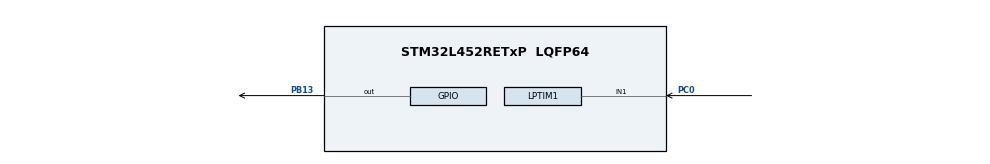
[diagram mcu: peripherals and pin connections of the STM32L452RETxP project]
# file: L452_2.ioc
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Mcu.Family=STM32L4
Mcu.Name=STM32L452RETxP
Mcu.Package=LQFP64
NVIC.LPTIM1_IRQn=true\:0\:0\:false\:false\:true\:true
NVIC.PriorityGroup=NVIC_PRIORITYGROUP_4
PA13\ (JTMS/SWDIO).Mode=Serial_Wire
PA13\ (JTMS/SWDIO).Signal=SYS_JTMS-SWDIO
PA14\ (JTCK/SWCLK).Mode=Serial_Wire
PA14\ (JTCK/SWCLK).Signal=SYS_JTCK-SWCLK
PB13.Signal=GPIO_Output
PC0.Mode=Counts_external_clock_standalone_1X_occur1
PC0.Signal=LPTIM1_IN1
ProjectManager.HeapSize=0x200
ProjectManager.StackSize=0x400
ProjectManager.TargetToolchain=MDK-ARM V5
RCC.HSE_VALUE=8000000
RCC.HSI48_VALUE=48000000
RCC.HSI_VALUE=16000000
RCC.LPTIM1CLockSelection=RCC_LPTIM1CLKSOURCE_LSI
RCC.LSE_VALUE=32768
RCC.MSI_VALUE=4000000
RCC.PWR_Regulator_Voltage_Scale=PWR_REGULATOR_VOLTAGE_SCALE2
RCC.VCOOutputFreq_Value=32000000
board=L452_2

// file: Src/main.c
/**
  ******************************************************************************
  * File Name          : main.c
  * Description        : Main program body
  ******************************************************************************
  ** This notice applies to any and all portions of this file
  * that are not between comment pairs USER CODE BEGIN and
  * USER CODE END. Other portions of this file, whether
  * inserted by the user or by software development tools
  * are owned by their respective copyright owners.
  *
  * COPYRIGHT(c) 2017 STMicroelectronics
  *
  * Redistribution and use in source and binary forms, with or without modification,
  * are permitted provided that the following conditions are met:
  *   1. Redistributions of source code must retain the above copyright notice,
  *      this list of conditions and the following disclaimer.
  *   2. Redistributions in binary form must reproduce the above copyright notice,
  *      this list of conditions and the following disclaimer in the documentation
  *      and/or other materials provided with the distribution.
  *   3. Neither the name of STMicroelectronics nor the names of its contributors
  *      may be used to endorse or promote products derived from this software
  *      without specific prior written permission.
  *
  * THIS SOFTWARE IS PROVIDED BY THE COPYRIGHT HOLDERS AND CONTRIBUTORS "AS IS"
  * AND ANY EXPRESS OR IMPLIED WARRANTIES, INCLUDING, BUT NOT LIMITED TO, THE
  * IMPLIED WARRANTIES OF MERCHANTABILITY AND FITNESS FOR A PARTICULAR PURPOSE ARE
  * DISCLAIMED. IN NO EVENT SHALL THE COPYRIGHT HOLDER OR CONTRIBUTORS BE LIABLE
  * FOR ANY DIRECT, INDIRECT, INCIDENTAL, SPECIAL, EXEMPLARY, OR CONSEQUENTIAL
  * DAMAGES (INCLUDING, BUT NOT LIMITED TO, PROCUREMENT OF SUBSTITUTE GOODS OR
  * SERVICES; LOSS OF USE, DATA, OR PROFITS; OR BUSINESS INTERRUPTION) HOWEVER
  * CAUSED AND ON ANY THEORY OF LIABILITY, WHETHER IN CONTRACT, STRICT LIABILITY,
  * OR TORT (INCLUDING NEGLIGENCE OR OTHERWISE) ARISING IN ANY WAY OUT OF THE USE
  * OF THIS SOFTWARE, EVEN IF ADVISED OF THE POSSIBILITY OF SUCH DAMAGE.
  *
  ******************************************************************************
  */

#include "main.h"
#include "stm32l4xx_hal.h"

LPTIM_HandleTypeDef hlptim1;

/* USER CODE BEGIN PV */
/* Private variables ---------------------------------------------------------*/

/* USER CODE END PV */

void SystemClock_Config(void);
static void MX_GPIO_Init(void);
static void MX_LPTIM1_Init(void);

/* USER CODE BEGIN PFP */
/* Private function prototypes -----------------------------------------------*/

/* USER CODE END PFP */

int main(void)
{

  /* MCU Configuration----------------------------------------------------------*/

  /* Reset of all peripherals, Initializes the Flash interface and the Systick. */
  HAL_Init();

  /* Configure the system clock */
  SystemClock_Config();

  /* Initialize all configured peripherals */
  MX_GPIO_Init();
  MX_LPTIM1_Init();

  /* USER CODE BEGIN 2 */
	HAL_PWREx_EnableGPIOPullUp(PWR_GPIO_A, GPIO_PIN_2);
    HAL_PWREx_EnableGPIOPullUp(PWR_GPIO_B, GPIO_PIN_3);
	HAL_PWREx_EnablePullUpPullDownConfig();

    __HAL_RCC_GPIOC_CLK_DISABLE();
    __HAL_RCC_GPIOH_CLK_DISABLE();
    __HAL_RCC_GPIOA_CLK_DISABLE();
    __HAL_RCC_GPIOE_CLK_DISABLE();
    __HAL_RCC_GPIOD_CLK_DISABLE();

	__HAL_FLASH_POWER_DOWN_ENABLE();
	HAL_LPTIM_Counter_Start_IT(&hlptim1, 4);

  /* USER CODE END 2 */

  /* Infinite loop */
  while (1)
  {

  /* USER CODE BEGIN 3 */
	HAL_PWREx_EnterSTOP2Mode(PWR_STOPENTRY_WFI);
	HAL_GPIO_TogglePin(GPIOB, GPIO_PIN_13);

  }
  /* USER CODE END 3 */

}

/** System Clock Configuration
*/
void SystemClock_Config(void)
{

  RCC_OscInitTypeDef RCC_OscInitStruct;
  RCC_ClkInitTypeDef RCC_ClkInitStruct;
  RCC_PeriphCLKInitTypeDef PeriphClkInit;

    /**Initializes the CPU, AHB and APB busses clocks
    */
  RCC_OscInitStruct.OscillatorType = RCC_OSCILLATORTYPE_LSI|RCC_OSCILLATORTYPE_MSI;
  RCC_OscInitStruct.LSIState = RCC_LSI_ON;
  RCC_OscInitStruct.MSIState = RCC_MSI_ON;
  RCC_OscInitStruct.MSICalibrationValue = 0;
  RCC_OscInitStruct.MSIClockRange = RCC_MSIRANGE_6;
  RCC_OscInitStruct.PLL.PLLState = RCC_PLL_NONE;
  if (HAL_RCC_OscConfig(&RCC_OscInitStruct) != HAL_OK)
  {
    _Error_Handler(__FILE__, __LINE__);
  }

    /**Initializes the CPU, AHB and APB busses clocks
    */
  RCC_ClkInitStruct.ClockType = RCC_CLOCKTYPE_HCLK|RCC_CLOCKTYPE_SYSCLK
                              |RCC_CLOCKTYPE_PCLK1|RCC_CLOCKTYPE_PCLK2;
  RCC_ClkInitStruct.SYSCLKSource = RCC_SYSCLKSOURCE_MSI;
  RCC_ClkInitStruct.AHBCLKDivider = RCC_SYSCLK_DIV1;
  RCC_ClkInitStruct.APB1CLKDivider = RCC_HCLK_DIV1;
  RCC_ClkInitStruct.APB2CLKDivider = RCC_HCLK_DIV1;

  if (HAL_RCC_ClockConfig(&RCC_ClkInitStruct, FLASH_LATENCY_0) != HAL_OK)
  {
    _Error_Handler(__FILE__, __LINE__);
  }

  PeriphClkInit.PeriphClockSelection = RCC_PERIPHCLK_LPTIM1;
  PeriphClkInit.Lptim1ClockSelection = RCC_LPTIM1CLKSOURCE_LSI;
  if (HAL_RCCEx_PeriphCLKConfig(&PeriphClkInit) != HAL_OK)
  {
    _Error_Handler(__FILE__, __LINE__);
  }

    /**Configure the main internal regulator output voltage
    */
  if (HAL_PWREx_ControlVoltageScaling(PWR_REGULATOR_VOLTAGE_SCALE2) != HAL_OK)
  {
    _Error_Handler(__FILE__, __LINE__);
  }

    /**Configure the Systick interrupt time
    */
  HAL_SYSTICK_Config(HAL_RCC_GetHCLKFreq()/1000);

    /**Configure the Systick
    */
  HAL_SYSTICK_CLKSourceConfig(SYSTICK_CLKSOURCE_HCLK);

  /* SysTick_IRQn interrupt configuration */
  HAL_NVIC_SetPriority(SysTick_IRQn, 0, 0);
}

/* LPTIM1 init function */
static void MX_LPTIM1_Init(void)
{

  hlptim1.Instance = LPTIM1;
  hlptim1.Init.Clock.Source = LPTIM_CLOCKSOURCE_ULPTIM;
  hlptim1.Init.Clock.Prescaler = LPTIM_PRESCALER_DIV1;
  hlptim1.Init.UltraLowPowerClock.Polarity = LPTIM_CLOCKPOLARITY_RISING;
  hlptim1.Init.UltraLowPowerClock.SampleTime = LPTIM_CLOCKSAMPLETIME_DIRECTTRANSITION;
  hlptim1.Init.Trigger.Source = LPTIM_TRIGSOURCE_SOFTWARE;
  hlptim1.Init.OutputPolarity = LPTIM_OUTPUTPOLARITY_HIGH;
  hlptim1.Init.UpdateMode = LPTIM_UPDATE_IMMEDIATE;
  hlptim1.Init.CounterSource = LPTIM_COUNTERSOURCE_EXTERNAL;
  hlptim1.Init.Input1Source = LPTIM_INPUT1SOURCE_GPIO;
  hlptim1.Init.Input2Source = LPTIM_INPUT2SOURCE_GPIO;
  if (HAL_LPTIM_Init(&hlptim1) != HAL_OK)
  {
    _Error_Handler(__FILE__, __LINE__);
  }

}

/** Configure pins as
        * Analog
        * Input
        * Output
        * EVENT_OUT
        * EXTI
        * Free pins are configured automatically as Analog (this feature is enabled through
        * the Code Generation settings)
*/
static void MX_GPIO_Init(void)
{

  GPIO_InitTypeDef GPIO_InitStruct;

  /* GPIO Ports Clock Enable */
  __HAL_RCC_GPIOC_CLK_ENABLE();
  __HAL_RCC_GPIOH_CLK_ENABLE();
  __HAL_RCC_GPIOA_CLK_ENABLE();
  __HAL_RCC_GPIOB_CLK_ENABLE();

  /*Configure GPIO pin Output Level */
  HAL_GPIO_WritePin(GPIOB, GPIO_PIN_13, GPIO_PIN_RESET);

  /*Configure GPIO pins : PC13 PC14 PC15 PC1
                           PC2 PC3 PC4 PC6
                           PC7 PC8 PC9 PC10
                           PC11 PC12 */
  GPIO_InitStruct.Pin = GPIO_PIN_13|GPIO_PIN_14|GPIO_PIN_15|GPIO_PIN_1
                          |GPIO_PIN_2|GPIO_PIN_3|GPIO_PIN_4|GPIO_PIN_6
                          |GPIO_PIN_7|GPIO_PIN_8|GPIO_PIN_9|GPIO_PIN_10
                          |GPIO_PIN_11|GPIO_PIN_12;
  GPIO_InitStruct.Mode = GPIO_MODE_ANALOG;
  GPIO_InitStruct.Pull = GPIO_NOPULL;
  HAL_GPIO_Init(GPIOC, &GPIO_InitStruct);

  /*Configure GPIO pins : PH0 PH1 PH3 */
  GPIO_InitStruct.Pin = GPIO_PIN_0|GPIO_PIN_1|GPIO_PIN_3;
  GPIO_InitStruct.Mode = GPIO_MODE_ANALOG;
  GPIO_InitStruct.Pull = GPIO_NOPULL;
  HAL_GPIO_Init(GPIOH, &GPIO_InitStruct);

  /*Configure GPIO pins : PA0 PA1 PA2 PA3
                           PA4 PA5 PA6 PA7
                           PA8 PA9 PA10 PA11
                           PA12 PA15 */
  GPIO_InitStruct.Pin = GPIO_PIN_0|GPIO_PIN_1|GPIO_PIN_2|GPIO_PIN_3
                          |GPIO_PIN_4|GPIO_PIN_5|GPIO_PIN_6|GPIO_PIN_7
                          |GPIO_PIN_8|GPIO_PIN_9|GPIO_PIN_10|GPIO_PIN_11
                          |GPIO_PIN_12|GPIO_PIN_15;
  GPIO_InitStruct.Mode = GPIO_MODE_ANALOG;
  GPIO_InitStruct.Pull = GPIO_NOPULL;
  HAL_GPIO_Init(GPIOA, &GPIO_InitStruct);

  /*Configure GPIO pins : PB0 PB1 PB2 PB10
                           PB11 PB12 PB14 PB15
                           PB3 PB4 PB5 PB6
                           PB7 PB8 PB9 */
  GPIO_InitStruct.Pin = GPIO_PIN_0|GPIO_PIN_1|GPIO_PIN_2|GPIO_PIN_10
                          |GPIO_PIN_11|GPIO_PIN_12|GPIO_PIN_14|GPIO_PIN_15
                          |GPIO_PIN_3|GPIO_PIN_4|GPIO_PIN_5|GPIO_PIN_6
                          |GPIO_PIN_7|GPIO_PIN_8|GPIO_PIN_9;
  GPIO_InitStruct.Mode = GPIO_MODE_ANALOG;
  GPIO_InitStruct.Pull = GPIO_NOPULL;
  HAL_GPIO_Init(GPIOB, &GPIO_InitStruct);

  /*Configure GPIO pin : PB13 */
  GPIO_InitStruct.Pin = GPIO_PIN_13;
  GPIO_InitStruct.Mode = GPIO_MODE_OUTPUT_PP;
  GPIO_InitStruct.Pull = GPIO_NOPULL;
  GPIO_InitStruct.Speed = GPIO_SPEED_FREQ_LOW;
  HAL_GPIO_Init(GPIOB, &GPIO_InitStruct);

}

void _Error_Handler(char * file, int line)
{
  while(1)
  {
  }
}

/************************ (C) COPYRIGHT STMicroelectronics *****END OF FILE****/
